# cc13x2_cc26x2 register map
File version: 2.1
CPU: CM4 r0p1, little endian, MPU, FPU, 3 interrupt priority bits
Registers are 32-bit, read-write, reset 0x0 unless marked. A register's access mark holds for its fields unless they carry their own. Offsets are from the block's base; [hi:lo] are bit positions; {n}, {i} and the like mark numbered series.

## CPU_DWT — Cortex-M's Data watchpoint and Trace (DWT)
Base 0xE0001000
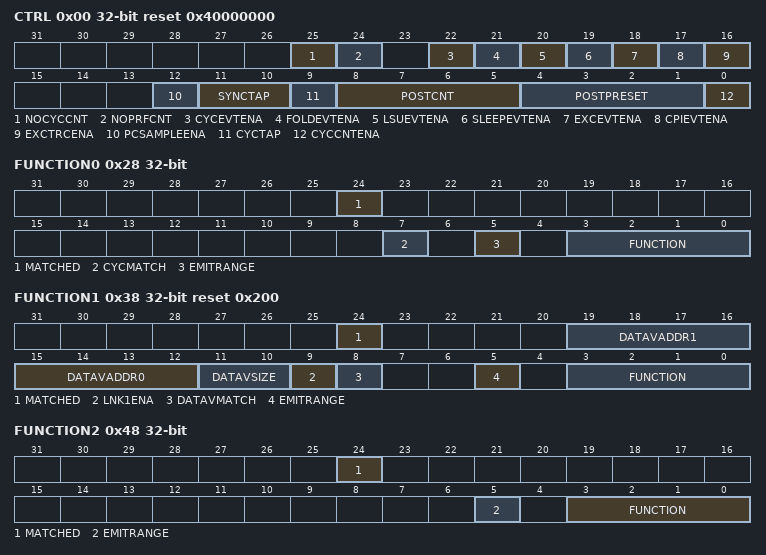
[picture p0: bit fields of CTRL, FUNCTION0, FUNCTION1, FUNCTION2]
0x00 CTRL reset 0x40000000 — Control se the DWT Control Register to enable the DWT unit.
  [25] NOCYCCNT, [24] NOPRFCNT, [22] CYCEVTENA, [21] FOLDEVTENA, [20] LSUEVTENA, [19] SLEEPEVTENA, [18] EXCEVTENA, [17] CPIEVTENA, [16] EXCTRCENA, [12] PCSAMPLEENA, [11:10] SYNCTAP, [9] CYCTAP, [8:5] POSTCNT, [4:1] POSTPRESET, [0] CYCCNTENA
0x04 CYCCNT — Current PC Sampler Cycle Count his register is used to count the number of core cycles. This counter can measure elapsed execution time. This is a free-running counter (this counter will not advance in power modes where free-running clock to CPU stops). The counter has three functions: : When CTRL.PCSAMPLEENA = 1, the PC is sampled and emitted when the selected tapped bit changes value (0 to 1 or 1 to 0) and any post-scalar value counts to 0. : When CTRL.CYCEVTENA = 1 , (and CTRL.PCSAMPLEENA = 0), an event is emitted when the selected tapped bit changes value (0 to 1 or 1 to 0) and any post-scalar value counts to 0. : Applications and debuggers can use the counter to measure elapsed execution time. By subtracting a start and an end time, an application can measure time between in-core clocks (other than when Halted in debug). This is valid to 2^32 core clock cycles (for example, almost 89.5 seconds at 48MHz).
0x08 CPICNT — CPI Count his register is used to count the total number of instruction cycles beyond the first cycle.
  [7:0] CPICNT
0x0C EXCCNT — Exception Overhead Count his register is used to count the total cycles spent in interrupt processing.
  [7:0] EXCCNT
0x10 SLEEPCNT — Sleep Count his register is used to count the total number of cycles during which the processor is sleeping.
  [7:0] SLEEPCNT
0x14 LSUCNT — LSU Count his register is used to count the total number of cycles during which the processor is processing an LSU operation beyond the first cycle.
  [7:0] LSUCNT
0x18 FOLDCNT — Fold Count his register is used to count the total number of folded instructions. The counter increments on each instruction which takes 0 cycles.
  [7:0] FOLDCNT
0x1C PCSR ro — Program Counter Sample his register is used to enable coarse-grained software profiling using a debug agent, without changing the currently executing code. If the core is not in debug state, the value returned is the instruction address of a recently executed instruction. If the core is in debug state, the value returned is 0xFFFFFFFF.
  [31:0] EIASAMPLE
{0x20+0x10*i} COMP{i} (i=0..3) — Comparator {i} his register is used to write the reference value for comparator {i}.
  [31:0] COMP
{0x24+0x10*i} MASK{i} (i=0..3) — Mask {i} se the DWT Mask Registers {i} to apply a mask to data addresses when matching against COMP{i}.
  [3:0] MASK
0x28 FUNCTION0 — Function 0 se the DWT Function Registers 0 to control the operation of the comparator 0. This comparator can: . Match against either the PC or the data address. This is controlled by CYCMATCH. This function is only available for comparator 0 (COMP0). . Emit data or PC couples, trigger the ETM, or generate a watchpoint depending on the operation defined by FUNCTION.
  [24] MATCHED, [7] CYCMATCH, [5] EMITRANGE, [3:0] FUNCTION
0x38 FUNCTION1 reset 0x200 — Function 1 se the DWT Function Registers 1 to control the operation of the comparator 1. This comparator can: . Perform data value comparisons if associated address comparators have performed an address match. This function is only available for comparator 1 (COMP1). . Emit data or PC couples, trigger the ETM, or generate a watchpoint depending on the operation defined by FUNCTION.
  [24] MATCHED, [19:16] DATAVADDR1, [15:12] DATAVADDR0, [11:10] DATAVSIZE, [9] LNK1ENA, [8] DATAVMATCH, [5] EMITRANGE, [3:0] FUNCTION
0x48 FUNCTION2 — Function 2 se the DWT Function Registers 2 to control the operation of the comparator 2. This comparator can emit data or PC couples, trigger the ETM, or generate a watchpoint depending on the operation defined by FUNCTION.
  [24] MATCHED, [5] EMITRANGE, [3:0] FUNCTION
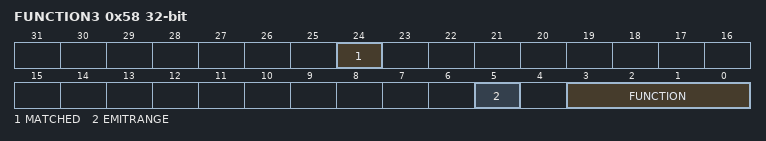
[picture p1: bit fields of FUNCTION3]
0x58 FUNCTION3 — Function 3 se the DWT Function Registers 3 to control the operation of the comparator 3. This comparator can emit data or PC couples, trigger the ETM, or generate a watchpoint depending on the operation defined by FUNCTION.
  [24] MATCHED, [5] EMITRANGE, [3:0] FUNCTION
